# CM85F register map
Registers are read-write, no defined reset value unless marked. A register's access mark holds for its fields unless they carry their own. Offsets are from the block's base; [hi:lo] are bit positions.

## RAS_Ext — Reliability, Availability, and Serviceability (RAS) Extension
Base 0xE0005000
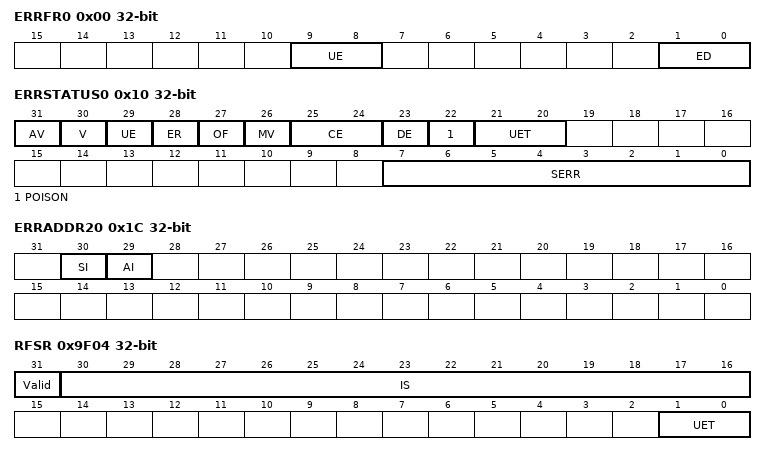
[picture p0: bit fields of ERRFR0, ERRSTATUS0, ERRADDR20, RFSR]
0x00 ERRFR0 ro — Error Record Feature Register describes the RAS features that are supported
  [9:8] UE — Enable Uncorrected error (UE) reporting as an external abort
    1=External abort response for uncorrected errors enabled
  [1:0] ED — Error reporting and logging
    1=Reporting and logging always enabled
0x08 ERRCTRL0 ro — This register is RES0
0x10 ERRSTATUS0 — Error Record Primary Status Register contains information about the Reliability, Availability, and Serviceability (RAS) event that is currently logged in record 0
  [31] AV — Address valid
    0=ERRADDR0 is not valid; 1=ERRADDR0 is valid
  [30] V — Status valid
    0=ERRSTATUS0 is not valid; 1=ERRSTATUS0 is valid
  [29] UE — Uncorrected errors (UEs)
    0=No uncorrectable errors detected; 1=At least one uncorrectable error is detected
  [28] ER — BusFault caused by RAS event
    0=No BusFault caused by RAS event has occurred; 1=BusFault caused by RAS event has occurred
  [27] OF — RAS events occurred since the last time ERRSTATUS0.V was cleared
    0=At most one RAS event has occurred since the last time ERRSTATUS0.V was cleared; 1=At least two RAS events have occurred since the last time ERRSTATUS.V was cleared
  [26] MV — Miscellaneous registers valid
    0=ERRMISC0 is not valid; 1=ERRMISC0 is valid
  [25:24] CE — Corrected errors
    0=Corrected errors (CEs) have not been detected; 1=At least one Corrected error (CE) has been detected
  [23] DE — Deferred errors
    0=No errors were deferred; 1=At least one error was deferred
  [22] POISON — BusFault due to RPOISON or TEBRn.POISON
    0=No BusFault due to RPOISON or TEBRn.POISON has occurred; 1=At least one BusFault due to RPOISON or TEBRn.POISON has occurred
  [21:20] UET — Uncorrectable error type
    0=Uncontainable error, Unrecoverable error (UC); 1=Uncorrectable, Recoverable error (UER)
  [7:0] SERR — Architecturally-defined primary error code
    0=No error; 2=TCM ECC error; 6=L1 data cache or instruction cache data RAM ECC error; 7=L1 data cache or instruction cache tag RAM ECC error
0x18 ERRADDR0 ro — Error Record Address Registers contains information about the address of the Reliability, Availability, and Serviceability (RAS) event in record 0
0x1C ERRADDR20 ro — Error Record Address Registers contains information about the address of the Reliability, Availability, and Serviceability (RAS) event in record 0
  [30] SI — Security information incorrect
    1=NS bit is not valid
  [29] AI — Address incorrect
    0=PADDR is valid; 1=PADDR is not valid
0x20 ERRMISC00 ro — Error Record Miscellaneous Register 0 this register is RES0
0x24 ERRMISC10 ro — Error Record Miscellaneous Register 10 error syndrome register for the event in record 0
  [1:0] TYPE — type of Reliability, Availability, and Serviceability (RAS) event logged
    0=Level 1 (L1) instruction cache Error Correcting Code (ECC); 1=L1 data cache ECC; 2=TCM ECC found by load or store executed by the processor; 3=TCM ECC found by access from Slave AHB (S-AHB)
0x28 ERRMISC20 ro — Error Record Miscellaneous Register 20 this register is RES0
0x2C ERRMISC30 ro — Error Record Miscellaneous Register 30 this register is RES0
0x30 ERRMISC40 ro — Error Record Miscellaneous Register 40 this register is RES0
0x34 ERRMISC50 ro — Error Record Miscellaneous Register 50 this register is RES0
0x38 ERRMISC60 ro — Error Record Miscellaneous Register 60 this register is RES0
0x3C ERRMISC70 ro — Error Record Miscellaneous Register 70 this register is RES0
0xE00 ERRGSR0 ro — Fault Group Status Register summarizes the valid error records
  [0] ERR0 — Error record 0 is valid
0xFC8 ERRDEVID ro — Error Record Device ID Register contains the number of error records that an implementation supports
  [15:0] NUM — Maximum Error Record Index+1
0x9F04 RFSR — Fault Status Register reports the fault status of Reliability, Availability, and Serviceability (RAS) related faults from Error Correcting Code (ECC) errors that are detected in the Level 1 (L1) instruction cache, data cache, and TCM
  [31] Valid — Indicates whether the register is valid
  [30:16] IS — Indicates the type of RAS exception that has occurred
    0=L1 instruction cache ECC; 1=L1 data cache ECC; 2=TCM ECC
  [1:0] UET — Error type
    0=Uncontainable error (UC). RAS exception is imprecise.; 1=Recoverable error (UER). RAS exception is precise.
